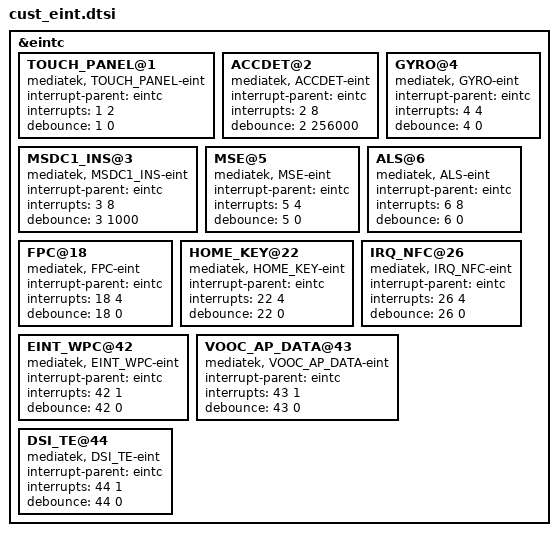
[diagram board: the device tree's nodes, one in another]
/*
 * Generated by MTK SP Drv_CodeGen Version 03.13.6  for MT6755. Copyright MediaTek Inc. (C) 2013.
 * Thu Jul 30 11:48:33 2026
 * Do Not Modify the File.
 */

/*************************
 * EINT DTSI File
*************************/

&eintc {
	TOUCH_PANEL@1 {
		compatible = "mediatek, TOUCH_PANEL-eint";
		interrupt-parent = <&eintc>;
		interrupts = <1 2>;
		debounce = <1 0>;
	};

	ACCDET@2 {
		compatible = "mediatek, ACCDET-eint";
		interrupt-parent = <&eintc>;
		interrupts = <2 8>;
		debounce = <2 256000>;
	};

	MSDC1_INS@3 {
		compatible = "mediatek, MSDC1_INS-eint";
		interrupt-parent = <&eintc>;
		interrupts = <3 8>;
		debounce = <3 1000>;
	};

	GYRO@4 {
		compatible = "mediatek, GYRO-eint";
		interrupt-parent = <&eintc>;
		interrupts = <4 4>;
		debounce = <4 0>;
	};

	MSE@5 {
		compatible = "mediatek, MSE-eint";
		interrupt-parent = <&eintc>;
		interrupts = <5 4>;
		debounce = <5 0>;
	};

	ALS@6 {
		compatible = "mediatek, ALS-eint";
		interrupt-parent = <&eintc>;
		interrupts = <6 8>;
		debounce = <6 0>;
	};

	FPC@18 {
		compatible = "mediatek, FPC-eint";
		interrupt-parent = <&eintc>;
		interrupts = <18 4>;
		debounce = <18 0>;
	};

	HOME_KEY@22 {
		compatible = "mediatek, HOME_KEY-eint";
		interrupt-parent = <&eintc>;
		interrupts = <22 4>;
		debounce = <22 0>;
	};

	IRQ_NFC@26 {
		compatible = "mediatek, IRQ_NFC-eint";
		interrupt-parent = <&eintc>;
		interrupts = <26 4>;
		debounce = <26 0>;
	};

	EINT_WPC@42 {
		compatible = "mediatek, EINT_WPC-eint";
		interrupt-parent = <&eintc>;
		interrupts = <42 1>;
		debounce = <42 0>;
	};

	VOOC_AP_DATA@43 {
		compatible = "mediatek, VOOC_AP_DATA-eint";
		interrupt-parent = <&eintc>;
		interrupts = <43 1>;
		debounce = <43 0>;
	};

	DSI_TE@44 {
		compatible = "mediatek, DSI_TE-eint";
		interrupt-parent = <&eintc>;
		interrupts = <44 1>;
		debounce = <44 0>;
	};

};
